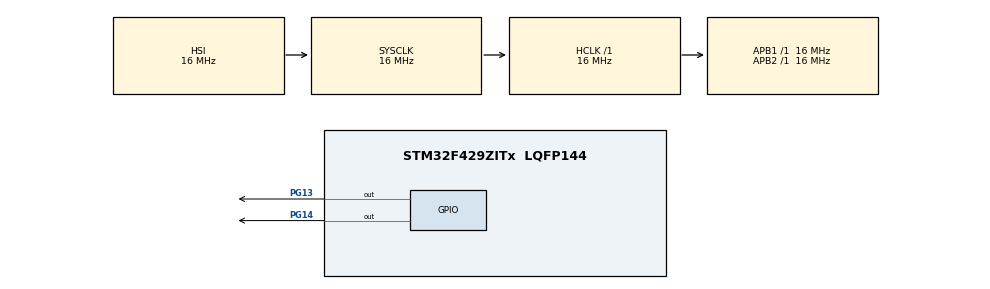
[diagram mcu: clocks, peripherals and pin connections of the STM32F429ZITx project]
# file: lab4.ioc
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FREERTOS.Tasks01=Task01,24,256,StartTask1,Default,NULL,Dynamic,NULL,NULL;Task02,24,128,StartTask02,Default,NULL,Dynamic,NULL,NULL
Mcu.Family=STM32F4
Mcu.Name=STM32F429ZITx
Mcu.Package=LQFP144
NVIC.PriorityGroup=NVIC_PRIORITYGROUP_4
NVIC.TIM6_DAC_IRQn=true\:15\:0\:false\:false\:true\:false\:false\:true\:true
NVIC.TimeBase=TIM6_DAC_IRQn
NVIC.TimeBaseIP=TIM6
PA13.Mode=Serial_Wire
PA13.Signal=SYS_JTMS-SWDIO
PA14.Mode=Serial_Wire
PA14.Signal=SYS_JTCK-SWCLK
PG13.Signal=GPIO_Output
PG14.Signal=GPIO_Output
ProjectManager.HeapSize=0x200
ProjectManager.StackSize=0x400
ProjectManager.TargetToolchain=STM32CubeIDE
RCC.AHBFreq_Value=16000000
RCC.APB1Freq_Value=16000000
RCC.APB2Freq_Value=16000000
RCC.CortexFreq_Value=16000000
RCC.HSE_VALUE=25000000
RCC.HSI_VALUE=16000000
RCC.LSE_VALUE=32768
RCC.SYSCLKFreq_VALUE=16000000
RCC.VCOOutputFreq_Value=192000000
VP_FREERTOS_VS_CMSIS_V2.Mode=CMSIS_V2
VP_SYS_VS_tim6.Mode=TIM6
board=custom

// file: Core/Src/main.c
/* USER CODE BEGIN Header */
/**
  ******************************************************************************
  * @file           : main.c
  * @brief          : Main program body
  ******************************************************************************
  * @attention
  *
  * Copyright (c) 2022 STMicroelectronics.
  * All rights reserved.
  *
  * This software is licensed under terms that can be found in the LICENSE file
  * in the root directory of this software component.
  * If no LICENSE file comes with this software, it is provided AS-IS.
  *
  ******************************************************************************
  */
/* USER CODE END Header */
#include "main.h"
#include "cmsis_os.h"

/* Definitions for Task01 */
osThreadId_t Task01Handle;
const osThreadAttr_t Task01_attributes = {
  .name = "Task01",
  .stack_size = 256 * 4,
  .priority = (osPriority_t) osPriorityNormal,
};
/* Definitions for Task02 */
osThreadId_t Task02Handle;
const osThreadAttr_t Task02_attributes = {
  .name = "Task02",
  .stack_size = 128 * 4,
  .priority = (osPriority_t) osPriorityNormal,
};

void SystemClock_Config(void);
static void MX_GPIO_Init(void);
void StartTask1(void *argument);
void StartTask02(void *argument);

int main(void)
{

  /* MCU Configuration--------------------------------------------------------*/

  /* Reset of all peripherals, Initializes the Flash interface and the Systick. */
  HAL_Init();

  /* Configure the system clock */
  SystemClock_Config();

  /* Initialize all configured peripherals */
  MX_GPIO_Init();

  /* Init scheduler */
  osKernelInitialize();

  /* Create the thread(s) */
  /* creation of Task01 */
  Task01Handle = osThreadNew(StartTask1, NULL, &Task01_attributes);

  /* creation of Task02 */
  Task02Handle = osThreadNew(StartTask02, NULL, &Task02_attributes);

  /* Start scheduler */
  osKernelStart();

  /* We should never get here as control is now taken by the scheduler */
  /* Infinite loop */
  while (1)
  {

  }
}

void SystemClock_Config(void)
{
  RCC_OscInitTypeDef RCC_OscInitStruct = {0};
  RCC_ClkInitTypeDef RCC_ClkInitStruct = {0};

  /** Configure the main internal regulator output voltage
  */
  __HAL_RCC_PWR_CLK_ENABLE();
  __HAL_PWR_VOLTAGESCALING_CONFIG(PWR_REGULATOR_VOLTAGE_SCALE3);

  /** Initializes the RCC Oscillators according to the specified parameters
  * in the RCC_OscInitTypeDef structure.
  */
  RCC_OscInitStruct.OscillatorType = RCC_OSCILLATORTYPE_HSI;
  RCC_OscInitStruct.HSIState = RCC_HSI_ON;
  RCC_OscInitStruct.HSICalibrationValue = RCC_HSICALIBRATION_DEFAULT;
  RCC_OscInitStruct.PLL.PLLState = RCC_PLL_NONE;
  if (HAL_RCC_OscConfig(&RCC_OscInitStruct) != HAL_OK)
  {
    Error_Handler();
  }

  /** Initializes the CPU, AHB and APB buses clocks
  */
  RCC_ClkInitStruct.ClockType = RCC_CLOCKTYPE_HCLK|RCC_CLOCKTYPE_SYSCLK
                              |RCC_CLOCKTYPE_PCLK1|RCC_CLOCKTYPE_PCLK2;
  RCC_ClkInitStruct.SYSCLKSource = RCC_SYSCLKSOURCE_HSI;
  RCC_ClkInitStruct.AHBCLKDivider = RCC_SYSCLK_DIV1;
  RCC_ClkInitStruct.APB1CLKDivider = RCC_HCLK_DIV1;
  RCC_ClkInitStruct.APB2CLKDivider = RCC_HCLK_DIV1;

  if (HAL_RCC_ClockConfig(&RCC_ClkInitStruct, FLASH_LATENCY_0) != HAL_OK)
  {
    Error_Handler();
  }
}

static void MX_GPIO_Init(void)
{
  GPIO_InitTypeDef GPIO_InitStruct = {0};

  /* GPIO Ports Clock Enable */
  __HAL_RCC_GPIOA_CLK_ENABLE();
  __HAL_RCC_GPIOG_CLK_ENABLE();

  /*Configure GPIO pin Output Level */
  HAL_GPIO_WritePin(GPIOG, GPIO_PIN_13|GPIO_PIN_14, GPIO_PIN_RESET);

  /*Configure GPIO pins : PG13 PG14 */
  GPIO_InitStruct.Pin = GPIO_PIN_13|GPIO_PIN_14;
  GPIO_InitStruct.Mode = GPIO_MODE_OUTPUT_PP;
  GPIO_InitStruct.Pull = GPIO_NOPULL;
  GPIO_InitStruct.Speed = GPIO_SPEED_FREQ_LOW;
  HAL_GPIO_Init(GPIOG, &GPIO_InitStruct);

}

void StartTask1(void *argument)
{
  /* USER CODE BEGIN 5 */
  /* Infinite loop */
  for(;;)
  {
//    osDelay(1);
	    HAL_GPIO_TogglePin(GPIOG, GPIO_PIN_13);
	    osDelay(1000);
  }
  /* USER CODE END 5 */
}

void StartTask02(void *argument)
{
  /* USER CODE BEGIN StartTask02 */
  /* Infinite loop */
  for(;;)
  {
//    osDelay(1);
	    HAL_GPIO_TogglePin(GPIOG, GPIO_PIN_14);
	    osDelay(2000);
  }
  /* USER CODE END StartTask02 */
}

void HAL_TIM_PeriodElapsedCallback(TIM_HandleTypeDef *htim)
{
  if (htim->Instance == TIM6) {
    HAL_IncTick();
  }
}

void Error_Handler(void)
{
  __disable_irq();
  while (1)
  {
  }
}
